# control_module register map
Vendor: Texas Instruments
Registers are 32-bit, access per field, no defined reset value unless marked. A register's access mark holds for its fields unless they carry their own. Offsets are as the file gives them; [hi:lo] are bit positions; {n}, {i} and the like mark numbered series; 'fields as' and 'values as' point back to an identical list.

## CONTROL_MODULE (part 3 of 3)
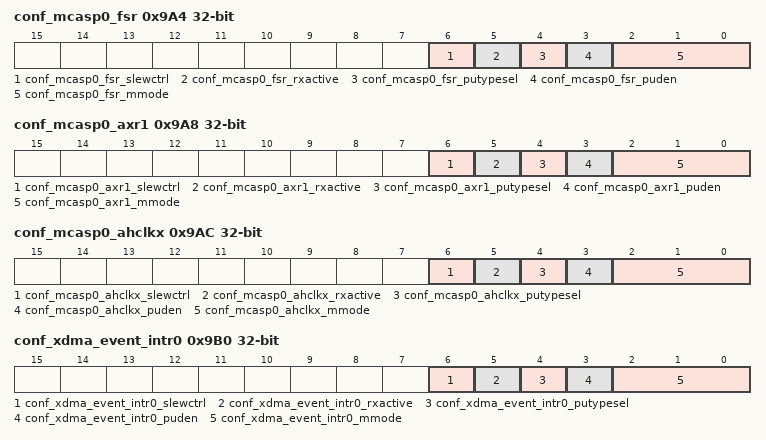
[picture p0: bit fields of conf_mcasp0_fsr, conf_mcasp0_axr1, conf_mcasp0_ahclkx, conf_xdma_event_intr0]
0x9A4 conf_mcasp0_fsr — See the device datasheet for information on default pin mux configurations. Note that the device ROM may change the default pin mux for certain pins based on the SYSBOOT mode settings.
  [6] conf_mcasp0_fsr_slewctrl rw — Select between faster or slower slew rate Reset value is pad-dependent.
    1=en_2_0x1 (Slow); 0=en_1_0x0 (Fast)
  [5] conf_mcasp0_fsr_rxactive rw — Input enable value for the PAD
    1=en_2_0x1 (Receiver enabled); 0=en_1_0x0 (Receiver disabled)
  [4] conf_mcasp0_fsr_putypesel rw — Pad pullup/pulldown type selection Reset value is pad-dependent.
    1=en_2_0x1 (Pullup selected); 0=en_1_0x0 (Pulldown selected)
  [3] conf_mcasp0_fsr_puden rw — Pad pullup/pulldown enable Reset value is pad-dependent.
    1=en_2_0x1 (Pullup/pulldown disabled); 0=en_1_0x0 (Pullup/pulldown enabled)
  [2:0] conf_mcasp0_fsr_mmode rw — Pad functional signal mux select. Reset value is pad-dependent.
0x9A8 conf_mcasp0_axr1 — See the device datasheet for information on default pin mux configurations. Note that the device ROM may change the default pin mux for certain pins based on the SYSBOOT mode settings.
  [6] conf_mcasp0_axr1_slewctrl rw — Select between faster or slower slew rate Reset value is pad-dependent.
    1=en_2_0x1 (Slow); 0=en_1_0x0 (Fast)
  [5] conf_mcasp0_axr1_rxactive rw — Input enable value for the PAD
    values as conf_mcasp0_fsr.conf_mcasp0_fsr_rxactive
  [4] conf_mcasp0_axr1_putypesel rw — Pad pullup/pulldown type selection Reset value is pad-dependent.
    1=en_2_0x1 (Pullup selected); 0=en_1_0x0 (Pulldown selected)
  [3] conf_mcasp0_axr1_puden rw — Pad pullup/pulldown enable Reset value is pad-dependent.
    values as conf_mcasp0_fsr.conf_mcasp0_fsr_puden
  [2:0] conf_mcasp0_axr1_mmode rw — Pad functional signal mux select. Reset value is pad-dependent.
0x9AC conf_mcasp0_ahclkx — See the device datasheet for information on default pin mux configurations. Note that the device ROM may change the default pin mux for certain pins based on the SYSBOOT mode settings.
  [6] conf_mcasp0_ahclkx_slewctrl rw — Select between faster or slower slew rate Reset value is pad-dependent.
    1=en_2_0x1 (Slow); 0=en_1_0x0 (Fast)
  [5] conf_mcasp0_ahclkx_rxactive rw — Input enable value for the PAD
    values as conf_mcasp0_fsr.conf_mcasp0_fsr_rxactive
  [4] conf_mcasp0_ahclkx_putypesel rw — Pad pullup/pulldown type selection Reset value is pad-dependent.
    1=en_2_0x1 (Pullup selected); 0=en_1_0x0 (Pulldown selected)
  [3] conf_mcasp0_ahclkx_puden rw — Pad pullup/pulldown enable Reset value is pad-dependent.
    values as conf_mcasp0_fsr.conf_mcasp0_fsr_puden
  [2:0] conf_mcasp0_ahclkx_mmode rw — Pad functional signal mux select. Reset value is pad-dependent.
0x9B0 conf_xdma_event_intr0 — See the device datasheet for information on default pin mux configurations. Note that the device ROM may change the default pin mux for certain pins based on the SYSBOOT mode settings.
  [6] conf_xdma_event_intr0_slewctrl rw — Select between faster or slower slew rate Reset value is pad-dependent.
    1=en_2_0x1 (Slow); 0=en_1_0x0 (Fast)
  [5] conf_xdma_event_intr0_rxactive rw — Input enable value for the PAD
    values as conf_mcasp0_fsr.conf_mcasp0_fsr_rxactive
  [4] conf_xdma_event_intr0_putypesel rw — Pad pullup/pulldown type selection Reset value is pad-dependent.
    1=en_2_0x1 (Pullup selected); 0=en_1_0x0 (Pulldown selected)
  [3] conf_xdma_event_intr0_puden rw — Pad pullup/pulldown enable Reset value is pad-dependent.
    values as conf_mcasp0_fsr.conf_mcasp0_fsr_puden
  [2:0] conf_xdma_event_intr0_mmode rw — Pad functional signal mux select. Reset value is pad-dependent.
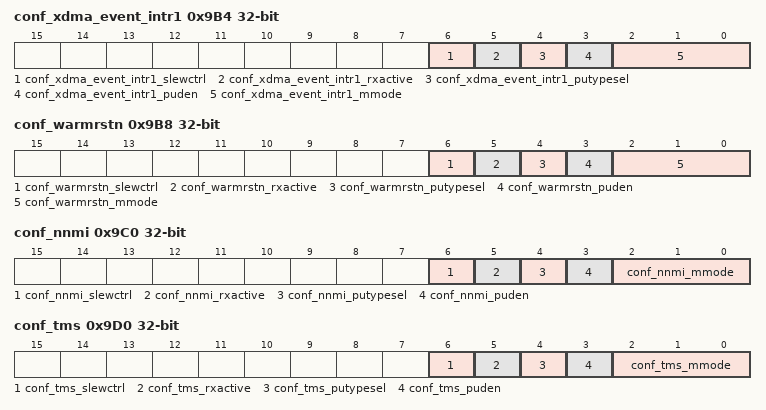
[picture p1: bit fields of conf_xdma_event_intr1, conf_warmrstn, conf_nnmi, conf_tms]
0x9B4 conf_xdma_event_intr1 — See the device datasheet for information on default pin mux configurations. Note that the device ROM may change the default pin mux for certain pins based on the SYSBOOT mode settings.
  [6] conf_xdma_event_intr1_slewctrl rw — Select between faster or slower slew rate Reset value is pad-dependent.
    1=en_2_0x1 (Slow); 0=en_1_0x0 (Fast)
  [5] conf_xdma_event_intr1_rxactive rw — Input enable value for the PAD
    values as conf_mcasp0_fsr.conf_mcasp0_fsr_rxactive
  [4] conf_xdma_event_intr1_putypesel rw — Pad pullup/pulldown type selection Reset value is pad-dependent.
    1=en_2_0x1 (Pullup selected); 0=en_1_0x0 (Pulldown selected)
  [3] conf_xdma_event_intr1_puden rw — Pad pullup/pulldown enable Reset value is pad-dependent.
    values as conf_mcasp0_fsr.conf_mcasp0_fsr_puden
  [2:0] conf_xdma_event_intr1_mmode rw — Pad functional signal mux select. Reset value is pad-dependent.
0x9B8 conf_warmrstn — See the device datasheet for information on default pin mux configurations. Note that the device ROM may change the default pin mux for certain pins based on the SYSBOOT mode settings.
  [6] conf_warmrstn_slewctrl rw — Select between faster or slower slew rate Reset value is pad-dependent.
    1=en_2_0x1 (Slow); 0=en_1_0x0 (Fast)
  [5] conf_warmrstn_rxactive rw — Input enable value for the PAD
    values as conf_mcasp0_fsr.conf_mcasp0_fsr_rxactive
  [4] conf_warmrstn_putypesel rw — Pad pullup/pulldown type selection Reset value is pad-dependent.
    1=en_2_0x1 (Pullup selected); 0=en_1_0x0 (Pulldown selected)
  [3] conf_warmrstn_puden rw — Pad pullup/pulldown enable Reset value is pad-dependent.
    values as conf_mcasp0_fsr.conf_mcasp0_fsr_puden
  [2:0] conf_warmrstn_mmode rw — Pad functional signal mux select. Reset value is pad-dependent.
0x9C0 conf_nnmi — See the device datasheet for information on default pin mux configurations. Note that the device ROM may change the default pin mux for certain pins based on the SYSBOOT mode settings.
  [6] conf_nnmi_slewctrl rw — Select between faster or slower slew rate Reset value is pad-dependent.
    1=en_2_0x1 (Slow); 0=en_1_0x0 (Fast)
  [5] conf_nnmi_rxactive rw — Input enable value for the PAD
    values as conf_mcasp0_fsr.conf_mcasp0_fsr_rxactive
  [4] conf_nnmi_putypesel rw — Pad pullup/pulldown type selection Reset value is pad-dependent.
    1=en_2_0x1 (Pullup selected); 0=en_1_0x0 (Pulldown selected)
  [3] conf_nnmi_puden rw — Pad pullup/pulldown enable Reset value is pad-dependent.
    values as conf_mcasp0_fsr.conf_mcasp0_fsr_puden
  [2:0] conf_nnmi_mmode rw — Pad functional signal mux select. Reset value is pad-dependent.
0x9D0 conf_tms — See the device datasheet for information on default pin mux configurations. Note that the device ROM may change the default pin mux for certain pins based on the SYSBOOT mode settings.
  [6] conf_tms_slewctrl rw — Select between faster or slower slew rate Reset value is pad-dependent.
    1=en_2_0x1 (Slow); 0=en_1_0x0 (Fast)
  [5] conf_tms_rxactive rw — Input enable value for the PAD
    values as conf_mcasp0_fsr.conf_mcasp0_fsr_rxactive
  [4] conf_tms_putypesel rw — Pad pullup/pulldown type selection Reset value is pad-dependent.
    1=en_2_0x1 (Pullup selected); 0=en_1_0x0 (Pulldown selected)
  [3] conf_tms_puden rw — Pad pullup/pulldown enable Reset value is pad-dependent.
    values as conf_mcasp0_fsr.conf_mcasp0_fsr_puden
  [2:0] conf_tms_mmode rw — Pad functional signal mux select. Reset value is pad-dependent.
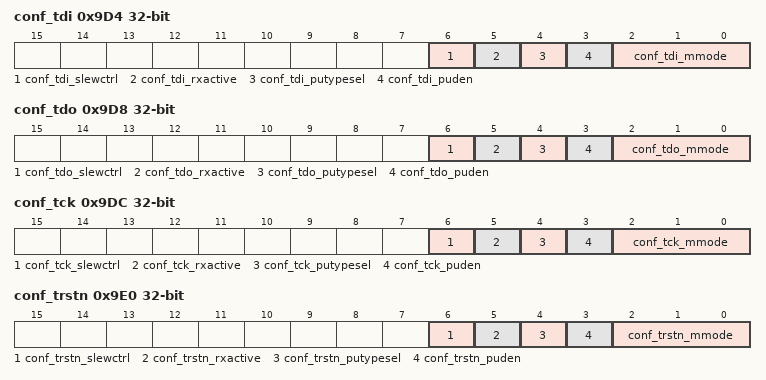
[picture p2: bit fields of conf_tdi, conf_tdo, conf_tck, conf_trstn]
0x9D4 conf_tdi — See the device datasheet for information on default pin mux configurations. Note that the device ROM may change the default pin mux for certain pins based on the SYSBOOT mode settings.
  [6] conf_tdi_slewctrl rw — Select between faster or slower slew rate Reset value is pad-dependent.
    1=en_2_0x1 (Slow); 0=en_1_0x0 (Fast)
  [5] conf_tdi_rxactive rw — Input enable value for the PAD
    values as conf_mcasp0_fsr.conf_mcasp0_fsr_rxactive
  [4] conf_tdi_putypesel rw — Pad pullup/pulldown type selection Reset value is pad-dependent.
    1=en_2_0x1 (Pullup selected); 0=en_1_0x0 (Pulldown selected)
  [3] conf_tdi_puden rw — Pad pullup/pulldown enable Reset value is pad-dependent.
    values as conf_mcasp0_fsr.conf_mcasp0_fsr_puden
  [2:0] conf_tdi_mmode rw — Pad functional signal mux select. Reset value is pad-dependent.
0x9D8 conf_tdo — See the device datasheet for information on default pin mux configurations. Note that the device ROM may change the default pin mux for certain pins based on the SYSBOOT mode settings.
  [6] conf_tdo_slewctrl rw — Select between faster or slower slew rate Reset value is pad-dependent.
    1=en_2_0x1 (Slow); 0=en_1_0x0 (Fast)
  [5] conf_tdo_rxactive rw — Input enable value for the PAD
    values as conf_mcasp0_fsr.conf_mcasp0_fsr_rxactive
  [4] conf_tdo_putypesel rw — Pad pullup/pulldown type selection Reset value is pad-dependent.
    1=en_2_0x1 (Pullup selected); 0=en_1_0x0 (Pulldown selected)
  [3] conf_tdo_puden rw — Pad pullup/pulldown enable Reset value is pad-dependent.
    values as conf_mcasp0_fsr.conf_mcasp0_fsr_puden
  [2:0] conf_tdo_mmode rw — Pad functional signal mux select. Reset value is pad-dependent.
0x9DC conf_tck — See the device datasheet for information on default pin mux configurations. Note that the device ROM may change the default pin mux for certain pins based on the SYSBOOT mode settings.
  [6] conf_tck_slewctrl rw — Select between faster or slower slew rate Reset value is pad-dependent.
    1=en_2_0x1 (Slow); 0=en_1_0x0 (Fast)
  [5] conf_tck_rxactive rw — Input enable value for the PAD
    values as conf_mcasp0_fsr.conf_mcasp0_fsr_rxactive
  [4] conf_tck_putypesel rw — Pad pullup/pulldown type selection Reset value is pad-dependent.
    1=en_2_0x1 (Pullup selected); 0=en_1_0x0 (Pulldown selected)
  [3] conf_tck_puden rw — Pad pullup/pulldown enable Reset value is pad-dependent.
    values as conf_mcasp0_fsr.conf_mcasp0_fsr_puden
  [2:0] conf_tck_mmode rw — Pad functional signal mux select. Reset value is pad-dependent.
0x9E0 conf_trstn — See the device datasheet for information on default pin mux configurations. Note that the device ROM may change the default pin mux for certain pins based on the SYSBOOT mode settings.
  [6] conf_trstn_slewctrl rw — Select between faster or slower slew rate Reset value is pad-dependent.
    1=en_2_0x1 (Slow); 0=en_1_0x0 (Fast)
  [5] conf_trstn_rxactive rw — Input enable value for the PAD
    values as conf_mcasp0_fsr.conf_mcasp0_fsr_rxactive
  [4] conf_trstn_putypesel rw — Pad pullup/pulldown type selection Reset value is pad-dependent.
    1=en_2_0x1 (Pullup selected); 0=en_1_0x0 (Pulldown selected)
  [3] conf_trstn_puden rw — Pad pullup/pulldown enable Reset value is pad-dependent.
    values as conf_mcasp0_fsr.conf_mcasp0_fsr_puden
  [2:0] conf_trstn_mmode rw — Pad functional signal mux select. Reset value is pad-dependent.
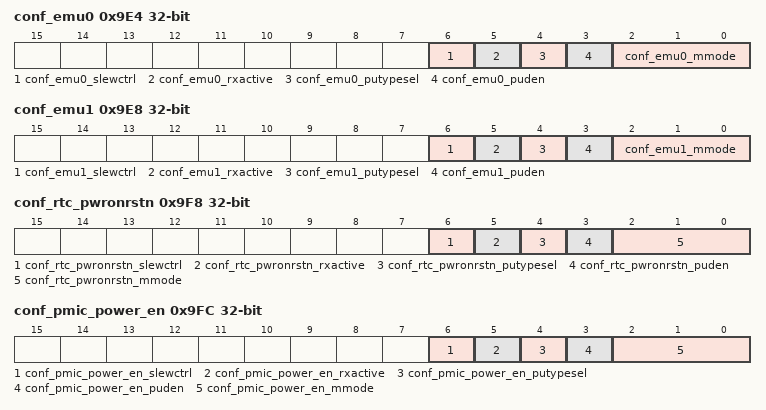
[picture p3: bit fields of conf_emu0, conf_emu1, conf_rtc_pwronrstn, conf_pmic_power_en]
0x9E4 conf_emu0 — See the device datasheet for information on default pin mux configurations. Note that the device ROM may change the default pin mux for certain pins based on the SYSBOOT mode settings.
  [6] conf_emu0_slewctrl rw — Select between faster or slower slew rate Reset value is pad-dependent.
    1=en_2_0x1 (Slow); 0=en_1_0x0 (Fast)
  [5] conf_emu0_rxactive rw — Input enable value for the PAD
    values as conf_mcasp0_fsr.conf_mcasp0_fsr_rxactive
  [4] conf_emu0_putypesel rw — Pad pullup/pulldown type selection Reset value is pad-dependent.
    1=en_2_0x1 (Pullup selected); 0=en_1_0x0 (Pulldown selected)
  [3] conf_emu0_puden rw — Pad pullup/pulldown enable Reset value is pad-dependent.
    values as conf_mcasp0_fsr.conf_mcasp0_fsr_puden
  [2:0] conf_emu0_mmode rw — Pad functional signal mux select. Reset value is pad-dependent.
0x9E8 conf_emu1 — See the device datasheet for information on default pin mux configurations. Note that the device ROM may change the default pin mux for certain pins based on the SYSBOOT mode settings.
  [6] conf_emu1_slewctrl rw — Select between faster or slower slew rate Reset value is pad-dependent.
    1=en_2_0x1 (Slow); 0=en_1_0x0 (Fast)
  [5] conf_emu1_rxactive rw — Input enable value for the PAD
    values as conf_mcasp0_fsr.conf_mcasp0_fsr_rxactive
  [4] conf_emu1_putypesel rw — Pad pullup/pulldown type selection Reset value is pad-dependent.
    1=en_2_0x1 (Pullup selected); 0=en_1_0x0 (Pulldown selected)
  [3] conf_emu1_puden rw — Pad pullup/pulldown enable Reset value is pad-dependent.
    values as conf_mcasp0_fsr.conf_mcasp0_fsr_puden
  [2:0] conf_emu1_mmode rw — Pad functional signal mux select. Reset value is pad-dependent.
0x9F8 conf_rtc_pwronrstn — See the device datasheet for information on default pin mux configurations. Note that the device ROM may change the default pin mux for certain pins based on the SYSBOOT mode settings.
  [6] conf_rtc_pwronrstn_slewctrl rw — Select between faster or slower slew rate Reset value is pad-dependent.
    1=en_2_0x1 (Slow); 0=en_1_0x0 (Fast)
  [5] conf_rtc_pwronrstn_rxactive rw — Input enable value for the PAD
    values as conf_mcasp0_fsr.conf_mcasp0_fsr_rxactive
  [4] conf_rtc_pwronrstn_putypesel rw — Pad pullup/pulldown type selection Reset value is pad-dependent.
    1=en_2_0x1 (Pullup selected); 0=en_1_0x0 (Pulldown selected)
  [3] conf_rtc_pwronrstn_puden rw — Pad pullup/pulldown enable Reset value is pad-dependent.
    values as conf_mcasp0_fsr.conf_mcasp0_fsr_puden
  [2:0] conf_rtc_pwronrstn_mmode rw — Pad functional signal mux select. Reset value is pad-dependent.
0x9FC conf_pmic_power_en — See the device datasheet for information on default pin mux configurations. Note that the device ROM may change the default pin mux for certain pins based on the SYSBOOT mode settings.
  [6] conf_pmic_power_en_slewctrl rw — Select between faster or slower slew rate Reset value is pad-dependent.
    1=en_2_0x1 (Slow); 0=en_1_0x0 (Fast)
  [5] conf_pmic_power_en_rxactive rw — Input enable value for the PAD
    values as conf_mcasp0_fsr.conf_mcasp0_fsr_rxactive
  [4] conf_pmic_power_en_putypesel rw — Pad pullup/pulldown type selection Reset value is pad-dependent.
    1=en_2_0x1 (Pullup selected); 0=en_1_0x0 (Pulldown selected)
  [3] conf_pmic_power_en_puden rw — Pad pullup/pulldown enable Reset value is pad-dependent.
    values as conf_mcasp0_fsr.conf_mcasp0_fsr_puden
  [2:0] conf_pmic_power_en_mmode rw — Pad functional signal mux select. Reset value is pad-dependent.
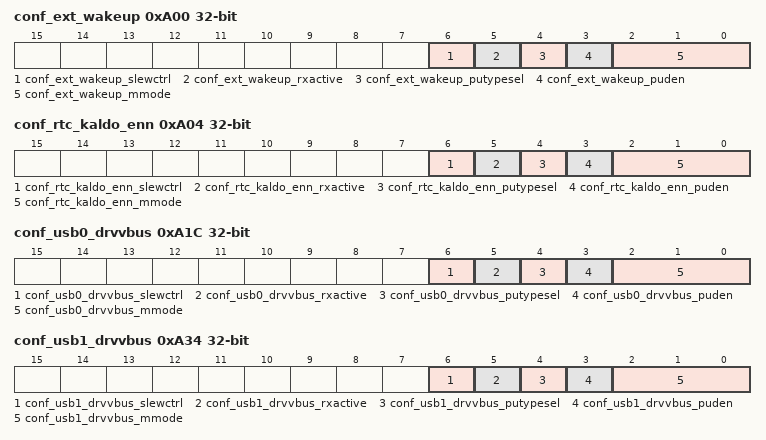
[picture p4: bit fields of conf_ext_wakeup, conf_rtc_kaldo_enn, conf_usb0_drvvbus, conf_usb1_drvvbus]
0xA00 conf_ext_wakeup — See the device datasheet for information on default pin mux configurations. Note that the device ROM may change the default pin mux for certain pins based on the SYSBOOT mode settings.
  [6] conf_ext_wakeup_slewctrl rw — Select between faster or slower slew rate Reset value is pad-dependent.
    1=en_2_0x1 (Slow); 0=en_1_0x0 (Fast)
  [5] conf_ext_wakeup_rxactive rw — Input enable value for the PAD
    values as conf_mcasp0_fsr.conf_mcasp0_fsr_rxactive
  [4] conf_ext_wakeup_putypesel rw — Pad pullup/pulldown type selection Reset value is pad-dependent.
    1=en_2_0x1 (Pullup selected); 0=en_1_0x0 (Pulldown selected)
  [3] conf_ext_wakeup_puden rw — Pad pullup/pulldown enable Reset value is pad-dependent.
    values as conf_mcasp0_fsr.conf_mcasp0_fsr_puden
  [2:0] conf_ext_wakeup_mmode rw — Pad functional signal mux select. Reset value is pad-dependent.
0xA04 conf_rtc_kaldo_enn — See the device datasheet for information on default pin mux configurations. Note that the device ROM may change the default pin mux for certain pins based on the SYSBOOT mode settings.
  [6] conf_rtc_kaldo_enn_slewctrl rw — Select between faster or slower slew rate Reset value is pad-dependent.
    1=en_2_0x1 (Slow); 0=en_1_0x0 (Fast)
  [5] conf_rtc_kaldo_enn_rxactive rw — Input enable value for the PAD
    values as conf_mcasp0_fsr.conf_mcasp0_fsr_rxactive
  [4] conf_rtc_kaldo_enn_putypesel rw — Pad pullup/pulldown type selection Reset value is pad-dependent.
    1=en_2_0x1 (Pullup selected); 0=en_1_0x0 (Pulldown selected)
  [3] conf_rtc_kaldo_enn_puden rw — Pad pullup/pulldown enable Reset value is pad-dependent.
    values as conf_mcasp0_fsr.conf_mcasp0_fsr_puden
  [2:0] conf_rtc_kaldo_enn_mmode rw — Pad functional signal mux select. Reset value is pad-dependent.
0xA1C conf_usb0_drvvbus — See the device datasheet for information on default pin mux configurations. Note that the device ROM may change the default pin mux for certain pins based on the SYSBOOT mode settings.
  [6] conf_usb0_drvvbus_slewctrl rw — Select between faster or slower slew rate Reset value is pad-dependent.
    1=en_2_0x1 (Slow); 0=en_1_0x0 (Fast)
  [5] conf_usb0_drvvbus_rxactive rw — Input enable value for the PAD
    values as conf_mcasp0_fsr.conf_mcasp0_fsr_rxactive
  [4] conf_usb0_drvvbus_putypesel rw — Pad pullup/pulldown type selection Reset value is pad-dependent.
    1=en_2_0x1 (Pullup selected); 0=en_1_0x0 (Pulldown selected)
  [3] conf_usb0_drvvbus_puden rw — Pad pullup/pulldown enable Reset value is pad-dependent.
    values as conf_mcasp0_fsr.conf_mcasp0_fsr_puden
  [2:0] conf_usb0_drvvbus_mmode rw — Pad functional signal mux select. Reset value is pad-dependent.
0xA34 conf_usb1_drvvbus — See the device datasheet for information on default pin mux configurations. Note that the device ROM may change the default pin mux for certain pins based on the SYSBOOT mode settings.
  [6] conf_usb1_drvvbus_slewctrl rw — Select between faster or slower slew rate Reset value is pad-dependent.
    1=en_2_0x1 (Slow); 0=en_1_0x0 (Fast)
  [5] conf_usb1_drvvbus_rxactive rw — Input enable value for the PAD
    values as conf_mcasp0_fsr.conf_mcasp0_fsr_rxactive
  [4] conf_usb1_drvvbus_putypesel rw — Pad pullup/pulldown type selection Reset value is pad-dependent.
    1=en_2_0x1 (Pullup selected); 0=en_1_0x0 (Pulldown selected)
  [3] conf_usb1_drvvbus_puden rw — Pad pullup/pulldown enable Reset value is pad-dependent.
    values as conf_mcasp0_fsr.conf_mcasp0_fsr_puden
  [2:0] conf_usb1_drvvbus_mmode rw — Pad functional signal mux select. Reset value is pad-dependent.
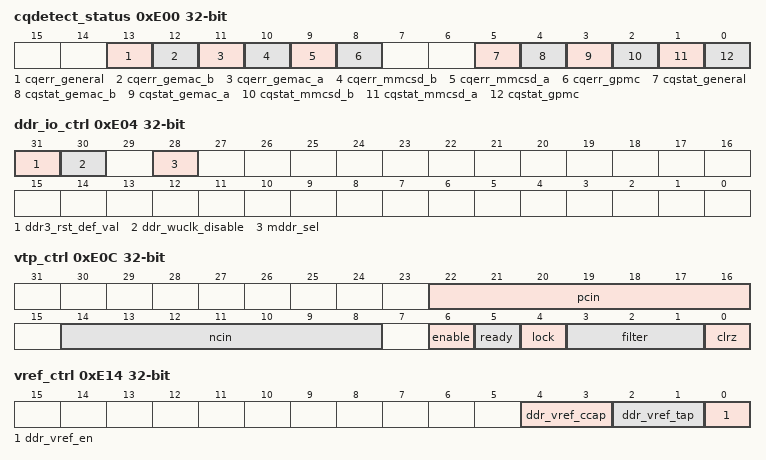
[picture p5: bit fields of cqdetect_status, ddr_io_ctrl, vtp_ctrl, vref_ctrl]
0xE00 cqdetect_status ro
  [13] cqerr_general — CQDetect Mode Error Status
  [12] cqerr_gemac_b — CQDetect Mode Error Status
  [11] cqerr_gemac_a — CQDetect Mode Error Status
  [10] cqerr_mmcsd_b — CQDetect Mode Error Status
  [9] cqerr_mmcsd_a — CQDetect Mode Error Status
  [8] cqerr_gpmc — CQDetect Mode Error Status
  [5] cqstat_general
    1=en_2_0x1 (IOs are 3.3V mode); 0=en_1_0x0 (IOs are 1.8V mode)
  [4] cqstat_gemac_b
    values as cqstat_general
  [3] cqstat_gemac_a
    values as cqstat_general
  [2] cqstat_mmcsd_b
    values as cqstat_general
  [1] cqstat_mmcsd_a
    values as cqstat_general
  [0] cqstat_gpmc
    values as cqstat_general
0xE04 ddr_io_ctrl
  [31] ddr3_rst_def_val rw — DDR3 reset default value
  [30] ddr_wuclk_disable rw — Disables the slow clock to WUCLKIN and ISOCLKIN of DDR emif SS and IOs (required for proper initialization, after which clock could be shut off).
    1=en_2_0x1 (clock is synchronously gated); 0=en_1_0x0 (free running SLOW (32k) clock)
  [28] mddr_sel rw
    1=en_2_0x1 (IOs set for mDDR (CMOS mode)); 0=en_1_0x0 (IOs set for DDR2/DDR3 (STL mode))
0xE0C vtp_ctrl
  [22:16] pcin ro — Default/reset values of 'P' for the VTP controller. See "Silicon Revision Functional Differences and Enhancements" in the device manual for differences in operation based on AM335x silicon revision.
  [14:8] ncin ro — Default/reset values of 'N' for the VTP controller. See "Silicon Revision Functional Differences and Enhancements" in the device manual for differences in operation based on AM335x silicon revision.
  [6] enable rw
    1=en_2_0x1 (Dynamic VTP compensation mode); 0=en_1_0x0 (VTP macro in bypass mode. P and N are driven from PCIN and NCIN.)
  [5] ready ro
    1=en_2_0x1 (Training sequence is complete); 0=en_1_0x0 (Training sequence is not complete)
  [4] lock rw
    1=en_2_0x1 (freeze dynamic update, pwrdn controller); 0=en_1_0x0 (Normal operation dynamic update)
  [3:1] filter rw — Digital filter bits to prevent the controller from making excessive number of changes.
  [0] clrz rw — clears flops, start count again, after low going pulse
0xE14 vref_ctrl
  [4:3] ddr_vref_ccap rw — Select for coupling cap for DDR
  [2:1] ddr_vref_tap rw — Select for int ref for DDR
  [0] ddr_vref_en rw — Active high internal reference enable for DDR
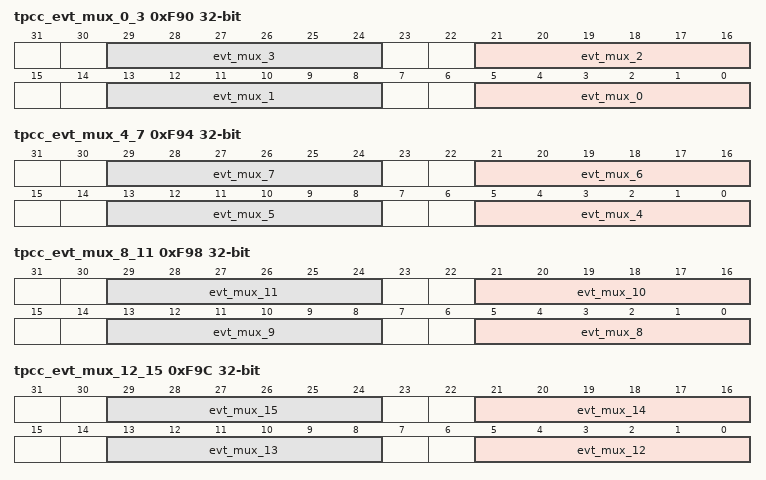
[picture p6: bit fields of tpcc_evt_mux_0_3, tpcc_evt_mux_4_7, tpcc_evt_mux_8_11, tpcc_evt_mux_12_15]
0xF90 tpcc_evt_mux_0_3
  [8n+5:8n] evt_mux_{n} rw (n=0..3) — Selects 1 of 64 inputs for DMA event {n}.
0xF94 tpcc_evt_mux_4_7
  [8n-27:8n-32] evt_mux_{n} rw (n=4..7) — Selects 1 of 64 inputs for DMA event {n}.
0xF98 tpcc_evt_mux_8_11
  [8n-59:8n-64] evt_mux_{n} rw (n=8..11) — Selects 1 of 64 inputs for DMA event {n}.
0xF9C tpcc_evt_mux_12_15
  [8n-91:8n-96] evt_mux_{n} rw (n=12..15) — Selects 1 of 64 inputs for DMA event {n}.
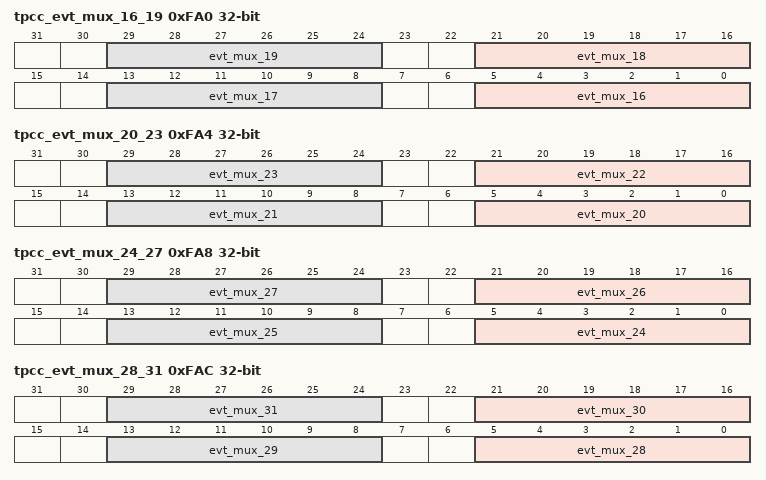
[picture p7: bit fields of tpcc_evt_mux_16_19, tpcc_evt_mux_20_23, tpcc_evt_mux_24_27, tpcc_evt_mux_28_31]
0xFA0 tpcc_evt_mux_16_19
  [8n-123:8n-128] evt_mux_{n} rw (n=16..19) — Selects 1 of 64 inputs for DMA event {n}.
0xFA4 tpcc_evt_mux_20_23
  [8n-155:8n-160] evt_mux_{n} rw (n=20..23) — Selects 1 of 64 inputs for DMA event {n}.
0xFA8 tpcc_evt_mux_24_27
  [8n-187:8n-192] evt_mux_{n} rw (n=24..27) — Selects 1 of 64 inputs for DMA event {n}.
0xFAC tpcc_evt_mux_28_31
  [8n-219:8n-224] evt_mux_{n} rw (n=28..31) — Selects 1 of 64 inputs for DMA event {n}.
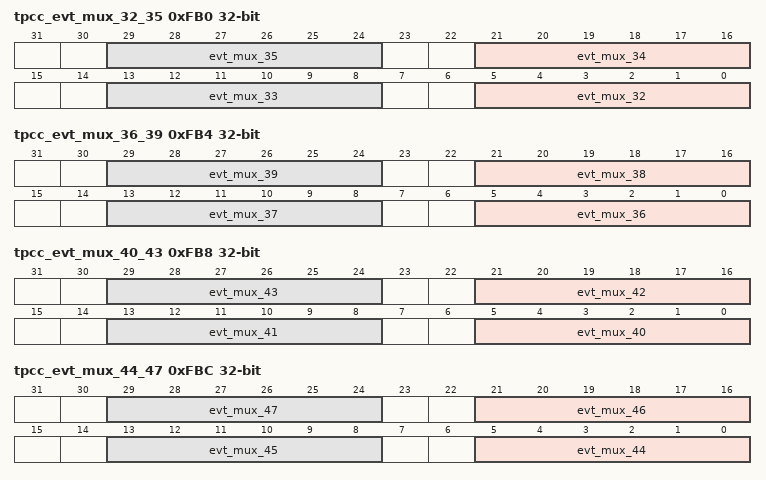
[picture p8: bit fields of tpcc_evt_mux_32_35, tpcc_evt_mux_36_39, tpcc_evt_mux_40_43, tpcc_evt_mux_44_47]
0xFB0 tpcc_evt_mux_32_35
  [8n-251:8n-256] evt_mux_{n} rw (n=32..35) — Selects 1 of 64 inputs for DMA event {n}.
0xFB4 tpcc_evt_mux_36_39
  [8n-283:8n-288] evt_mux_{n} rw (n=36..39) — Selects 1 of 64 inputs for DMA event {n}.
0xFB8 tpcc_evt_mux_40_43
  [8n-315:8n-320] evt_mux_{n} rw (n=40..43) — Selects 1 of 64 inputs for DMA event {n}.
0xFBC tpcc_evt_mux_44_47
  [8n-347:8n-352] evt_mux_{n} rw (n=44..47) — Selects 1 of 64 inputs for DMA event {n}.
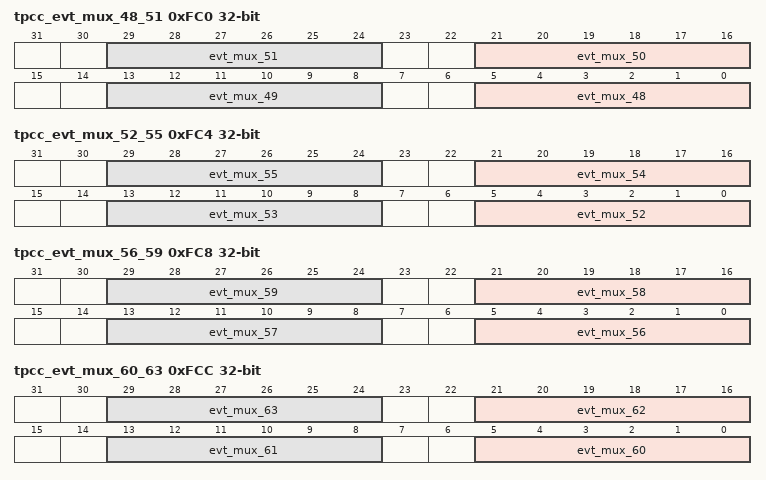
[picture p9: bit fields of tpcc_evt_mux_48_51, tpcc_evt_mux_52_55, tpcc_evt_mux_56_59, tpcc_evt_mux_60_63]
0xFC0 tpcc_evt_mux_48_51
  [8n-379:8n-384] evt_mux_{n} rw (n=48..51) — Selects 1 of 64 inputs for DMA event {n}.
0xFC4 tpcc_evt_mux_52_55
  [8n-411:8n-416] evt_mux_{n} rw (n=52..55) — Selects 1 of 64 inputs for DMA event {n}.
0xFC8 tpcc_evt_mux_56_59
  [8n-443:8n-448] evt_mux_{n} rw (n=56..59) — Selects 1 of 64 inputs for DMA event {n}.
0xFCC tpcc_evt_mux_60_63
  [8n-475:8n-480] evt_mux_{n} rw (n=60..63) — Selects 1 of 64 inputs for DMA event {n}.
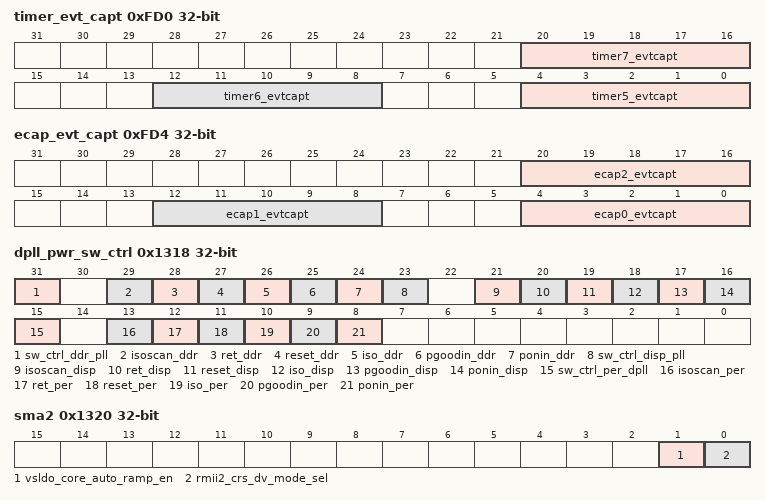
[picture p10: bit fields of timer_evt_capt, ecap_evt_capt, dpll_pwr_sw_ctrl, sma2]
0xFD0 timer_evt_capt
  [20:16] timer7_evtcapt rw — Timer 7 event capture mux.
  [12:8] timer6_evtcapt rw — Timer 6 event capture mux.
  [4:0] timer5_evtcapt rw — Timer 5 event capture mux.
0xFD4 ecap_evt_capt
  [20:16] ecap2_evtcapt rw — ECAP2 event capture mux.
  [12:8] ecap1_evtcapt rw — ECAP1 event capture mux.
  [4:0] ecap0_evtcapt rw — ECAP0 event capture mux.
0xFD8 adc_evt_capt
  [3:0] adc_evtcapt rw — ECAP0 event capture mux.
0x1000 reset_iso
  [0] iso_control rw
    1=en_2_0x1 (Ethernet Switch is isolated.); 0=en_1_0x0 (Ethernet Switch is not isolated.)
0x1318 dpll_pwr_sw_ctrl — The DPLL_PWR_SW_CTRL register, in conjunction with the DPLL_PWR_SW_STATUS register, can be used to power off the digital power domain of the 3 DPLLS DDR, DISP, PER to save leakage power in deep-sleep power modes. This register gives control over the power switch signals of the individual DPLLS. A specific sequence has to be followed while programming the RET, PONIN, PGOODIN, ISO and RESET signals to put the PLLs in to low power mode and bring it out of low power mode. In normal operating mode, the PRCM controls the RESET of the DPLLS. The RET, PONIN, PGOODIN and ISO are tied off. An over-ride bit is provided in this register SW_CTRL_*_RESET, which when set allows S/W to control the RESET, RET, PONIN, PGOODIN and ISO of the DPLLs to enable entry/exit into DPLL low power modes.
  [31] sw_ctrl_ddr_pll rw — Enable software control over DDR DPLL RET, RESET, ISO, PGOODIN, PONIN for power savings.
    1=en_2_0x1 (Controlled by corresponding bits in this register.); 0=en_1_0x0 (PRCM controls the DPLL reset, RET = 0, ISO = 0, PGOODIN = 1, PONIN = 1.)
  [29] isoscan_ddr rw — Drives ISOSCAN of DDR PLL.
  [28] ret_ddr rw — Drives RET signal of DDR PLL.
  [27] reset_ddr rw — Drives RESET of DDR DPLL.
  [26] iso_ddr rw — Drives ISO of DDR DPLL.
  [25] pgoodin_ddr rw — Drives PGOODIN of DDR DPLL.
  [24] ponin_ddr rw — Drives PONIN of DDR DPLL.
  [23] sw_ctrl_disp_pll rw — Enable software control over DISP DPLL RET, RESET, ISO, PGOODIN, PONIN for power savings.
    values as sw_ctrl_ddr_pll
  [21] isoscan_disp rw — Drives ISOSCAN of DISP PLL.
  [20] ret_disp rw — Drives RET of DISP DPLL.
  [19] reset_disp rw — Drives RESET of DISP DPLL.
  [18] iso_disp rw — Drives ISO of DISP DPLL.
  [17] pgoodin_disp rw — Drives PGOODIN of DISP DPLL.
  [16] ponin_disp rw — Drives PONIN of DISP DPLL.
  [15] sw_ctrl_per_dpll rw — Enable software control over PER DPLL RET, RESET, ISO, PGOODIN, PONIN for power savings.
    values as sw_ctrl_ddr_pll
  [13] isoscan_per rw — Drives ISOSCAN of PER PLL.
  [12] ret_per rw — Drives RET of PER DPLL.
  [11] reset_per rw — Drives RESET signal of PER DPLL.
  [10] iso_per rw — Drives ISO signal of PER DPLL.
  [9] pgoodin_per rw — Drives PGOODIN signal of PER DPLL.
  [8] ponin_per rw — Drives PONIN signal of PER DPLL.
0x131C ddr_cke_ctrl
  [0] ddr_cke_ctrl rw — CKE from EMIF/DDRPHY is ANDed with this bit.
    1=en_2_0x1 (Normal operation. CKE is now controlled by EMIF/DDR PHY.); 0=en_1_0x0 (CKE to memories gated off to zero. External DRAM memories will not able to register DDR commands from device)
0x1320 sma2 — The VSLDO_CORE_AUTO_RAMP_EN bit when set, allows the VSLDO to be put into retention during deep-sleep thereby enabling lower power consumption. Since the VSLDO is shared b/w WKUP M3 memories and CORE memories, the VSLDO has to be brought out of retention on any wakeup event. The hardware scheme mentioned below achieves this purpose.
  [1] vsldo_core_auto_ramp_en rw
    1=en_2_0x1 (Allows hardware to bring VSLDO out of retention on wakeup from deep-sleep.); 0=en_1_0x0 (PRCM controls VSLDO.)
  [0] rmii2_crs_dv_mode_sel rw
    1=en_2_0x1 (Select RMII2_CRS_DV on GPMC_A9 pin in MODE3.); 0=en_1_0x0 (Select MMC2_DAT7 on GPMC_A9 pin in MODE3.)
0x1324 m3_txev_eoi
  [0] m3_txev_eoi rw — TXEV (Event) from M3 processor is a pulse signal connected as intertupt to MPU IRQ(78) Since MPU expects level signals. The TXEV pulse from M3 is converted to a level in glue logic. The logic works as follows: On a 0-1 transition on TXEV, the IRQ[78] is set. For clearing the interrupt, S/W must do the following: S/W must clear the IRQ[78] by writing a 1 to M3_TXEV_EOI bit in this registe This bit is sticky and for re-arming the IRQ[78], S/W must write a 0 to this field in the ISR
{0x1328+4i} ipc_msg_reg{i} rw (i=0..7) — This register is typically used for messaging between Cortex A8 and CortexM3 (WKUP). See the section "Functional Sequencing for Power Management with Cortex M3" in the device manual for specific information on how the IPC_MSG_REG registers are used to communicate with the Cortex-M3 firmware.
  [31:0] ipc_msg_reg{i} — Inter Processor Messaging Register
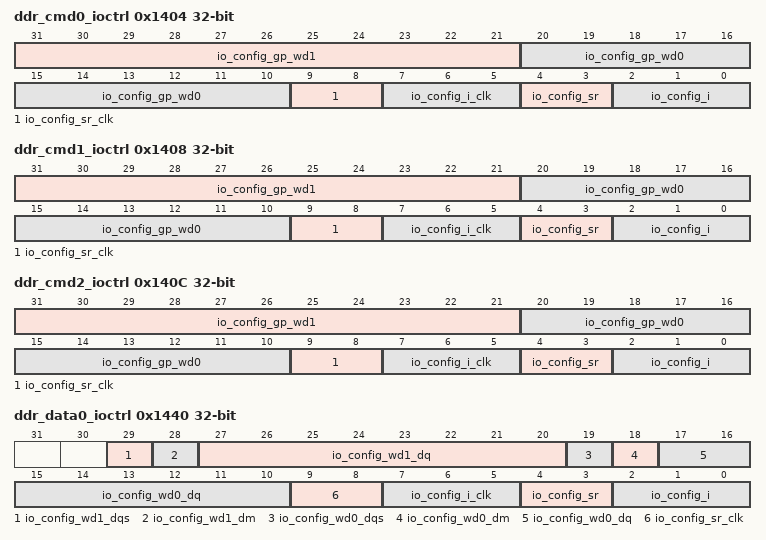
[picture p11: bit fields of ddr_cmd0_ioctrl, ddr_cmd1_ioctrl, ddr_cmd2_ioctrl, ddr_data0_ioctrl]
0x1404 ddr_cmd0_ioctrl
  [31:21] io_config_gp_wd1 rw — There are 2 bits per IO: io_config_gp_wd1 and io_config_gp_wd0. For example: macro pin 0: WD1 is bit 21, WD0 is bit 10. macro pin 1: WD1 is bit 22, WD0 is bit 11. ... macro pin 10: WD1 is bit 31, WD0 is bit 20. See the DDR PHY to IO Pin Mapping table in the Control Module Functional Description section of the device manual for a mapping of macro bits to I/Os. WD1:WD0
    17=en_4_0x11 (Weak keeper enabled); 16=en_3_0x10 (Weak pulldown enabled); 1=en_2_0x01 (Weak pullup enabled); 0=en_1_0x00 (Pullup/Pulldown disabled)
  [20:10] io_config_gp_wd0 rw — There are 2 bits per IO: io_config_gp_wd1 and io_config_gp_wd0. For example: macro pin 0: WD1 is bit 21, WD0 is bit 10. macro pin 1: WD1 is bit 22, WD0 is bit 11. ... macro pin 10: WD1 is bit 31, WD0 is bit 20. See the DDR PHY to IO Pin Mapping table in the Control Module Functional Description section of the device manual for a mapping of macro bits to I/Os. WD1:WD0
    values as io_config_gp_wd1
  [9:8] io_config_sr_clk ro — 2 bit to program clock IO Pads (DDR_CK/DDR_CKN) output slew rate. These connect as SR1, SR0 to the corresponding DDR IO buffer. See the DDR Slew Rate Control Settings table in the Control Module Functional Description section of the device manual for a definition of these bits.
  [7:5] io_config_i_clk rw — 3-bit configuration input to program clock IO pads (DDR_CK/DDR_CKN) output impedance. These connect as I2, I1, I0 to the corresponding DDR IO buffer. See the DDR Impedance Control Settings table in the Control Module Functional Description section of the device manual for a definition of these bits.
  [4:3] io_config_sr rw — 2 bit to program addr/cmd IO Pads output slew rate. These connect as SR1, SR0 to the corresponding DDR IO buffer. See the DDR Slew Rate Control Settings table in the Control Module Functional Description section of the device manual for a definition of these bits.
  [2:0] io_config_i rw — 3-bit configuration input to program addr/cmd IO output impedance. These connect as I2, I1, I0 to the corresponding DDR IO buffer. See the DDR Impedance Control Settings table in the Control Module Functional Description section of the device manual for a definition of these bits.
0x1408 ddr_cmd1_ioctrl rw
  [31:21] io_config_gp_wd1 — There are 2 bits per IO: io_config_gp_wd1 and io_config_gp_wd0. For example: macro pin 0: WD1 is bit 21, WD0 is bit 10. macro pin 1: WD1 is bit 22, WD0 is bit 11. ... macro pin 10: WD1 is bit 31, WD0 is bit 20. See the DDR PHY to IO Pin Mapping table in the Control Module Functional Description section of the device manual for a mapping of macro bits to I/Os. WD1:WD0
    values as ddr_cmd0_ioctrl.io_config_gp_wd1
  [20:10] io_config_gp_wd0 — There are 2 bits per IO: io_config_gp_wd1 and io_config_gp_wd0. For example: macro pin 0: WD1 is bit 21, WD0 is bit 10. macro pin 1: WD1 is bit 22, WD0 is bit 11. ... macro pin 10: WD1 is bit 31, WD0 is bit 20. See the DDR PHY to IO Pin Mapping table in the Control Module Functional Description section of the device manual for a mapping of macro bits to I/Os. WD1:WD0
    values as ddr_cmd0_ioctrl.io_config_gp_wd1
  [9:8] io_config_sr_clk — 2 bit to program clock IO Pads (DDR_CK/DDR_CKN) output slew rate. These connect as SR1, SR0 to the corresponding DDR IO buffer. See the DDR Slew Rate Control Settings table in the Control Module Functional Description section of the device manual for a definition of these bits.
  [7:5] io_config_i_clk — 3-bit configuration input to program clock IO pads (DDR_CK/DDR_CKN) output impedance. These connect as I2, I1, I0 to the corresponding DDR IO buffer. See the DDR Impedance Control Settings table in the Control Module Functional Description section of the device manual for a definition of these bits.
  [4:3] io_config_sr — 2 bit to program addr/cmd IO Pads output slew rate. These connect as SR1, SR0 to the corresponding DDR IO buffer. See the DDR Slew Rate Control Settings table in the Control Module Functional Description section of the device manual for a definition of these bits.
  [2:0] io_config_i — 3-bit configuration input to program addr/cmd IO output impedance. These connect as I2, I1, I0 to the corresponding DDR IO buffer. See the DDR Impedance Control Settings table in the Control Module Functional Description section of the device manual for a definition of these bits.
0x140C ddr_cmd2_ioctrl rw
  fields as ddr_cmd1_ioctrl
0x1440 ddr_data0_ioctrl
  [29] io_config_wd1_dqs rw — Input that selects pullup or pulldown for DDR_DQS0 and DDR_DQSn0. Used with io_config_wd0_dqs to define pullup/pulldown according to the following: WD1: WD0
  [28] io_config_wd1_dm rw — Input that selects pullup or pulldown for DM. Used with io_config_wd0_dm to define pullup/pulldown according to the following: WD1:WD0
  [27:20] io_config_wd1_dq rw — Input that selects pullup or pulldown for DQ. There are 2 bits per IO: io_config_wd1_dq and io_config_wd0_dq. For example: macro pin 0: WD1 is bit 20 WD0 is bit 10. macro pin 1: WD1 is bit 21, WD0 is bit 11 . ... macro pin 7: WD1 is bit 27, WD0 is bit 17. See the DDR PHY to IO Pin Mapping table in the Control Module Functional Description section of the device manual for a mapping of macro bits to I/Os. WD1:WD0
    values as ddr_cmd0_ioctrl.io_config_gp_wd1
  [19] io_config_wd0_dqs rw — Input that selects pullup or pulldown for DDR_DQS0 and DDR_DQSn0. Used with io_config_wd1_dqs to define pullup/pulldown according to the following: WD1:WD0
  [18] io_config_wd0_dm rw — Input that selects pullup or pulldown for DM. Used with io_config_wd1_dm to define pullup/pulldown according to the following: WD1:WD0
  [17:10] io_config_wd0_dq rw — Input that selects pullup or pulldown for DQ. There are 2 bits per IO: io_config_wd1_dq and io_config_wd0_dq. For example: macro pin 0: WD1 is bit 20, WD0 is bit 10. macro pin 1: WD1 is bit 21, WD0 is bit 11. ... macro pin 7: WD1 is bit 27, WD0 is bit 17. See the DDR PHY to IO Pin Mapping table in the Control Module Functional Description section of the device manual for a mapping of macro bits to I/Os. WD1:WD0
    values as ddr_cmd0_ioctrl.io_config_gp_wd1
  [9:8] io_config_sr_clk rw — 2 bit to program clock IO Pads (DDR_DQS/DDR_DQSn) output slew rate. These connect as SR1, SR0 of the corresponding IO buffer. See the DDR Slew Rate Control Settings table in the Control Module Functional Description section of the device manual for a definition of these bits.
  [7:5] io_config_i_clk rw — 3-bit configuration input to program clock IO pads (DDR_DQS/DDR_DQSn) output impedance. These connect as I2, I1, I0 of the corresponding buffer. See the DDR Impedance Control Settings table in the Control Module Functional Description section of the device manual for a definition of these bits.
  [4:3] io_config_sr rw — 2 bit to program data IO Pads output slew rate. These connect as SR1, SR0 of the corresponding IO buffer. See the DDR Slew Rate Control Settings table in the Control Module Functional Description section of the device manual for a definition of these bits.
  [2:0] io_config_i rw — 3-bit configuration input to program data IO output impedance. These connect as I2, I1, I0 of the corresponding IO buffer. See the DDR Impedance Control Settings table in the Control Module Functional Description section of the device manual for a definition of these bits.
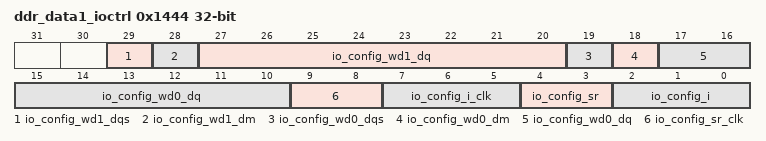
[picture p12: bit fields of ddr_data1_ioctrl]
0x1444 ddr_data1_ioctrl
  [29] io_config_wd1_dqs rw — Input that selects pullup or pulldown for DDR_DQS1 and DDR_DQSn1. Used with io_config_wd0_dqs to define pullup/pulldown according to the following: WD1:WD0
  [28] io_config_wd1_dm rw — Input that selects pullup or pulldown for DM. Used with io_config_wd0_dm to define pullup/pulldown according to the following: WD1:WD0
  [27:20] io_config_wd1_dq rw — Input that selects pullup or pulldown for DQ. There are 2 bits per IO: io_config_wd1_dq and io_config_wd0_dq. For example: macro pin 0: WD1 is bit 20, WD0 is bit 10. macro pin 1: WD1 is bit 21, WD0 is bit 11. ... macro pin 7: WD1 is bit 27, WD0 is bit 17. See the DDR PHY to IO Pin Mapping table in the Control Module Functional Description section of the device manual for a mapping of macro bits to I/Os. WD1:WD0
    values as ddr_cmd0_ioctrl.io_config_gp_wd1
  [19] io_config_wd0_dqs rw — Input that selects pullup or pulldown for DDR_DQS1 and DDR_DQSn1. Used with io_config_wd1_dqs to define pullup/pulldown according to the following: WD1:WD0
  [18] io_config_wd0_dm rw — Input that selects pullup or pulldown for DM. Used with io_config_wd1_dm to define pullup/pulldown according to the following: WD1:WD0
  [17:10] io_config_wd0_dq rw — Input that selects pullup or pulldown for DQ. There are 2 bits per IO: io_config_wd1_dq and io_config_wd0_dq. For example: macro pin 0: WD1 is bit 20, WD0 is bit 10. macro pin 1: WD1 is bit 21, WD0 is bit 11. ... macro pin 7: WD1 is bit 27, WD0 is bit 17. See the DDR PHY to IO Pin Mapping table in the Control Module Functional Description section of the device manual for a mapping of macro bits to I/Os. WD1:WD0
    values as ddr_cmd0_ioctrl.io_config_gp_wd1
  [9:8] io_config_sr_clk rw — Two-bit to program clock IO Pads (DDR_DQS/DDR_DQSn) output slew rate. These connect as SR1, SR0 of the corresponding IO buffer. See the DDR Slew Rate Control Settings table in the Control Module Functional Description section of the device manual for a definition of these bits.
  [7:5] io_config_i_clk rw — Three-bit configuration input to program clock IO pads (DDR_DQS/DDR_DQSn) output impedance. These connect as I2, I1, I0 of the corresponding buffer. See the DDR Impedance Control Settings table in the Control Module Functional Description section of the device manual for a definition of these bits.
  [4:3] io_config_sr rw — Two-bit to program data IO Pads output slew rate. These connect as SR1, SR0 of the corresponding IO buffer. See the DDR Slew Rate Control Settings table in the Control Module Functional Description section of the device manual for a definition of these bits.
  [2:0] io_config_i rw — Three-bit configuration input to program data IO output impedance. These connect as I2, I1, I0 of the corresponding IO buffer. See the DDR Impedance Control Settings table in the Control Module Functional Description section of the device manual for a definition of these bits.
